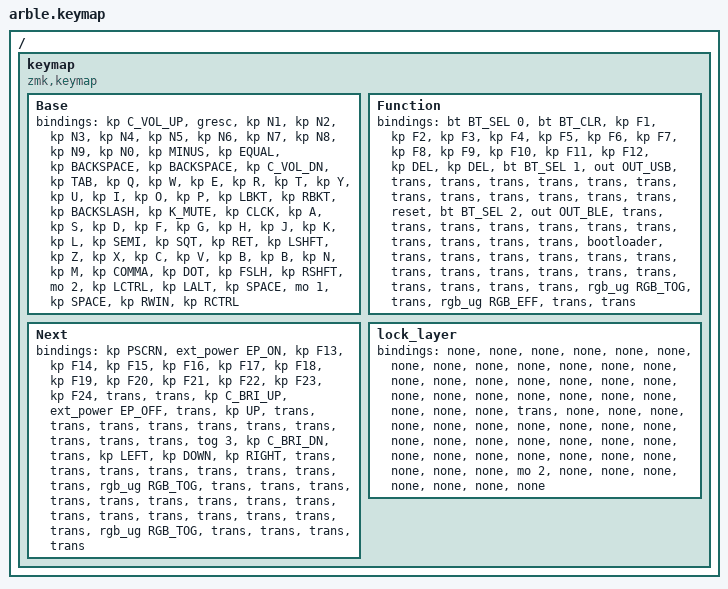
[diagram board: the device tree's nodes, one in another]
/*
 * Copyright (c) 2021 Nick Winans
 *
 * SPDX-License-Identifier: MIT
 */

#include <behaviors.dtsi>
#include <dt-bindings/zmk/keys.h>
#include <dt-bindings/zmk/bt.h>
#include <dt-bindings/zmk/outputs.h>
#include <dt-bindings/zmk/rgb.h>
#include <dt-bindings/zmk/ext_power.h>

/ {
    keymap {
        compatible = "zmk,keymap";

        Base {
        
            bindings = <
 &kp C_VOL_UP  &gresc  &kp N1  &kp N2  &kp N3  &kp N4  &kp N5  &kp N6  &kp N7  &kp N8  &kp N9  &kp N0  &kp MINUS  &kp EQUAL  &kp BACKSPACE  &kp BACKSPACE  &kp C_VOL_DN  &kp TAB   &kp Q   &kp W   &kp E   &kp R   &kp T   &kp Y   &kp U   &kp I   &kp O   &kp P  &kp LBKT  &kp RBKT  &kp BACKSLASH  &kp K_MUTE  &kp CLCK   &kp A   &kp S   &kp D   &kp F   &kp G   &kp H   &kp J   &kp K   &kp L  &kp SEMI  &kp SQT  &kp RET  &kp LSHFT   &kp Z   &kp X   &kp C   &kp V   &kp B   &kp B   &kp N   &kp M  &kp COMMA  &kp DOT  &kp FSLH  &kp RSHFT   &mo 2  &kp LCTRL  &kp LALT  &kp SPACE   &mo 1  &kp SPACE  &kp RWIN  &kp RCTRL
            >;
        };

        Function {

            bindings = <
 &bt BT_SEL 0  &bt BT_CLR  &kp F1  &kp F2  &kp F3  &kp F4  &kp F5  &kp F6  &kp F7  &kp F8  &kp F9  &kp F10  &kp F11  &kp F12  &kp DEL  &kp DEL  &bt BT_SEL 1  &out OUT_USB  &trans  &trans  &trans  &trans  &trans  &trans  &trans  &trans  &trans  &trans  &trans  &trans  &reset  &bt BT_SEL 2  &out OUT_BLE  &trans  &trans  &trans  &trans  &trans  &trans  &trans  &trans  &trans  &trans  &trans  &bootloader  &trans  &trans  &trans  &trans  &trans  &trans  &trans  &trans  &trans  &trans  &trans  &trans  &trans  &trans  &trans  &trans  &rgb_ug RGB_TOG  &trans  &rgb_ug RGB_EFF  &trans  &trans
            >;
        };

        Next {

            bindings = <
 &kp PSCRN  &ext_power EP_ON  &kp F13  &kp F14  &kp F15  &kp F16  &kp F17  &kp F18  &kp F19  &kp F20  &kp F21  &kp F22  &kp F23  &kp F24  &trans  &trans  &kp C_BRI_UP  &ext_power EP_OFF  &trans  &kp UP  &trans  &trans  &trans  &trans  &trans  &trans  &trans  &trans  &trans  &trans  &tog 3  &kp C_BRI_DN  &trans  &kp LEFT  &kp DOWN  &kp RIGHT  &trans  &trans  &trans  &trans  &trans  &trans  &trans  &trans  &rgb_ug RGB_TOG  &trans  &trans  &trans  &trans  &trans  &trans  &trans  &trans  &trans  &trans  &trans  &trans  &trans  &trans  &trans  &trans  &rgb_ug RGB_TOG  &trans  &trans  &trans  &trans
            >;
        };

        lock_layer {
            bindings = <
  &none   &none   &none   &none   &none   &none   &none   &none   &none   &none   &none   &none   &none   &none   &none   &none   &none   &none   &none   &none   &none   &none   &none   &none   &none   &none   &none   &none   &none   &none  &trans   &none   &none   &none   &none   &none   &none   &none   &none   &none   &none   &none   &none   &none   &none   &none   &none   &none   &none   &none   &none   &none   &none   &none   &none   &none   &none   &none   &mo 2   &none   &none   &none   &none   &none   &none   &none
            >;
        };
    };
};
